# STM32F733 register map
File version: 1.4
CPU: CM7 r0p1, little endian, MPU, FPU, 4 interrupt priority bits
Registers are 32-bit, read-write, reset 0x0 unless marked. A register's access mark holds for its fields unless they carry their own. Offsets are from the block's base; [hi:lo] are bit positions; {n}, {i} and the like mark numbered series.

## TIM6 — Basic timers
Base 0x40001000
Same registers: TIM7 0x40001400
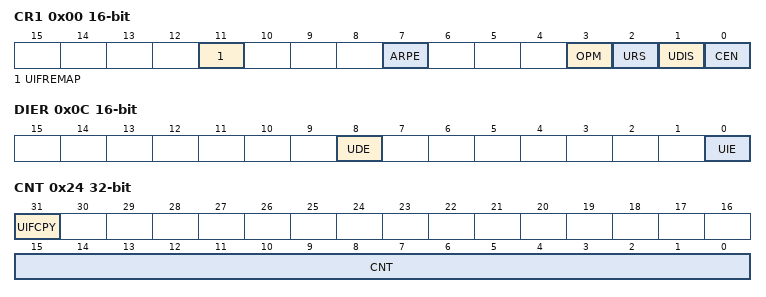
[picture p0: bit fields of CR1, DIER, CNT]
0x00 CR1 16-bit — control register 1
  [11] UIFREMAP — UIF status bit remapping
  [7] ARPE — Auto-reload preload enable
    0=Disabled (TIMx_APRR register is not buffered); 1=Enabled (TIMx_APRR register is buffered)
  [3] OPM — One-pulse mode
    0=Disabled (Counter is not stopped at update event); 1=Enabled (Counter stops counting at the next update event (clearing the CEN bit))
  [2] URS — Update request source
    0=AnyEvent (Any of counter overflow/underflow, setting UG, or update through slave mode, generates an update interrupt or DMA request); 1=CounterOnly (Only counter overflow/underflow generates an update interrupt or DMA request)
  [1] UDIS — Update disable
    0=Enabled (Update event enabled); 1=Disabled (Update event disabled)
  [0] CEN — Counter enable
    0=Disabled (Counter disabled); 1=Enabled (Counter enabled)
0x04 CR2 16-bit — control register 2
  [6:4] MMS — Master mode selection
    0=Reset (Use UG bit from TIMx_EGR register); 1=Enable (Use CNT bit from TIMx_CEN register); 2=Update (Use the update event)
0x0C DIER 16-bit — DMA/Interrupt enable register
  [8] UDE — Update DMA request enable
    0=Disabled (Update DMA request disabled); 1=Enabled (Update DMA request enabled)
  [0] UIE — Update interrupt enable
    0=Disabled (Update interrupt disabled); 1=Enabled (Update interrupt enabled)
0x10 SR 16-bit — status register
  [0] UIF write-0-clears — Update interrupt flag
    on read: 0=NoUpdateOccurred; 1=UpdatePending (Update interrupt pending) | on write: 0=Clear flag
0x14 EGR wo — event generation register
  [0] UG — Update generation
    1=Update (Re-initializes the timer counter and generates an update of the registers.)
0x24 CNT access per field — counter
  [31] UIFCPY ro — UIF Copy
  [15:0] CNT rw — Low counter value
0x24 CNT16 16-bit (alternate view of CNT) — 16-bit counter register
  [15:0] CNT — counter value
0x28 PSC 16-bit — prescaler
  [15:0] PSC — Prescaler value
0x2C ARR 16-bit reset 0xFFFF — auto-reload register
  [15:0] ARR — Low Auto-reload value

## CRC — Cryptographic processor
Base 0x40023000
0x00 DR reset 0xFFFFFFFF — Data register
  [31:0] DR — Data Register
0x00 DR8 8-bit reset 0xFF (alternate view of DR) — Data register - byte sized
  [7:0] DR8 — Data register bits
0x00 DR16 16-bit reset 0xFFFF (alternate view of DR) — Data register - half-word sized
  [15:0] DR16 — Data register bits
0x04 IDR — Independent Data register
  [7:0] IDR
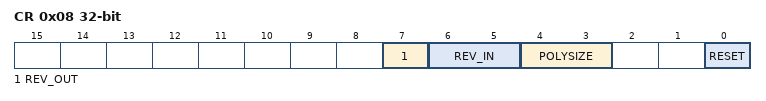
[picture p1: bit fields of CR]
0x08 CR wo — Control register
  [7] REV_OUT — Reverse output data
    0=Normal (Bit order not affected); 1=Reversed (Bit reversed output)
  [6:5] REV_IN — Reverse input data
    0=Normal (Bit order not affected); 1=Byte (Bit reversal done by byte); 2=HalfWord (Bit reversal done by half-word); 3=Word (Bit reversal done by word)
  [4:3] POLYSIZE — Polynomial size
    0=32-bit polynomial; 1=16-bit polynomial; 2=8-bit polynomial; 3=7-bit polynomial
  [0] RESET — RESET bit
    1=Resets the CRC calculation unit and sets the data register to 0xFFFF FFFF
0x10 INIT — Initial CRC value
  [31:0] INIT — Programmable initial CRC value
0x14 POL — CRC polynomial
  [31:0] POL — Programmable polynomial

## CRYP — Cryptographic processor
Base 0x50060000
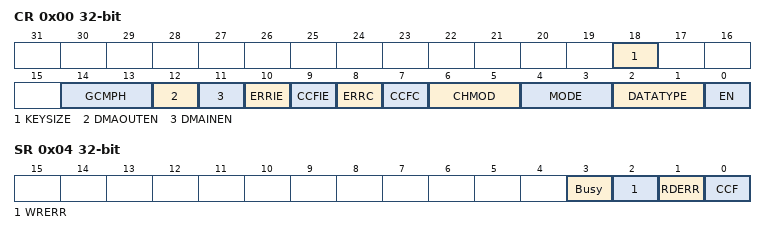
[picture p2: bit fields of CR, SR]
0x00 CR — control register
  [18] KEYSIZE — Key size selection
  [14:13] GCMPH — Used only for GCM, GMAC and CMAC algorithms and has no effect when other
  [12] DMAOUTEN — Enable DMA management of data output phase
  [11] DMAINEN — Enable DMA management of data input phase
  [10] ERRIE — Error interrupt enable
  [9] CCFIE — CCF flag interrupt enable
  [8] ERRC — Error clear
  [7] CCFC — Computation complete flag clear
  [6:5] CHMOD — AES chaining mode
  [4:3] MODE — AES operating mode
  [2:1] DATATYPE — Data type selection (for data in and data out to/from the cryptographic block)
  [0] EN — AES enable
0x04 SR ro — status register
  [3] Busy — Busy flag
  [2] WRERR — Write error flag
  [1] RDERR — Read error flag
  [0] CCF — Computation complete flag
0x08 DINR — data input register
  [31:0] DINR — Data input
0x0C DOUTR ro — data output register
  [31:0] DOUTR — Data output
0x10 KEYR0 — key register
  [30:0] KEYR0 — Data output register
0x14 KEYR1 — key register
  [31:0] KEYR1 — Data output register
0x18 KEYR2 ro — key register
  [30:0] KEYR2 — Data output register
0x1C KEYR3 ro — key register
  [31:0] KEYR3 — Data output register
0x20 IVR0 — initialization vector register
{0x20+4i} IVR{i} (i=1..3) — initialization vector register
  [31:0] IVR{i} — Initialization vector register
{0x20+4i} KEYR{i} (i=4..7) — key registers
  [31:0] KEYR{i} — Data output register
{0x40+4i} SUSP{i}R (i=0..2) — Suspend registers
  [31:0] SUSP{i}R — AES Suspend
0x4C SUSP3R — Suspend registers
  [31:0] SUSP3R — IV127
{0x40+4i} SUSP{i}R (i=4..7) — Suspend registers
  [31:0] SUSP{i}R — AES Suspend
